VERSION "v1"

NS_ :

BS_:

BU_: ECU0 ECU1 ECU2 ECU3

VAL_TABLE_ TFS 0 "FALSE" 1 "TRUE";
VAL_TABLE_ LRS 0 "LEFT" 1 "RIGHT";
VAL_TABLE_ UDS 0 "UP" 1 "DOWN";
VAL_TABLE_ FooSignalValues ;

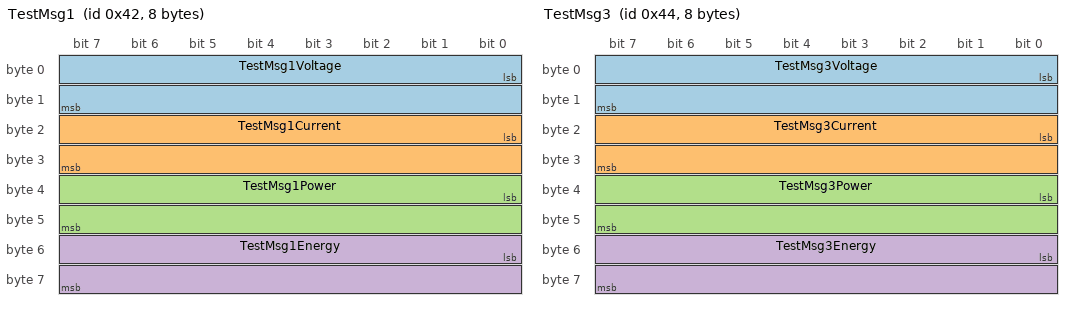
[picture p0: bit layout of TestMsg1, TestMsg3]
BO_ 66 TestMsg1: 8 ECU1
 SG_ TestMsg1Voltage : 0|16@1- (0.001,0) [-32.768|32.767] "V" ECU2,ECU1,ECU0
 SG_ TestMsg1Current : 16|16@1- (0.001,0) [-32.768|32.767] "A" ECU2
 SG_ TestMsg1Power : 32|16@1+ (0.001,0) [0|65.535] "W" ECU2
 SG_ TestMsg1Energy : 48|16@1+ (0.001,100) [100|165.535] "kWh" ECU2

BO_ 67 TestMsg2: 8 ECU1
 SG_ TestMsg2Signal : 0|16@1+ (1,0) [0|10] "Enum" ECU2

BO_ 68 TestMsg3: 8 ECU1
 SG_ TestMsg3Voltage : 0|16@1- (0.001,0) [-32.768|32.767] "V" ECU2
 SG_ TestMsg3Current : 16|16@1- (0.001,1) [-32.768|32.767] "A" ECU2
 SG_ TestMsg3Power : 32|16@1+ (1.0e-3,0) [0|65.535] "W" ECU2
 SG_ TestMsg3Energy : 48|16@1+ (0.001,1e2) [1.e2|165.535] "kWh" ECU2

BO_ 69 TestMsg4: 8 ECU2
 SG_ Muxer M : 0|8@1+ (1,0) [0|3] "" ECU1
 SG_ Muxed0 m0 : 8|8@1+ (1,0) [0|255] "" ECU1
 SG_ Muxed1 m1 : 8|8@1+ (1,0) [0|255] "" ECU1
 SG_ Muxed2 m2 : 8|8@1+ (1,0) [0|255] "" ECU1
 SG_ M : 16|8@1+ (1,0) [0|255] "" ECU1
 SG_ m0 m0 : 24|8@1+ (1,0) [0|255] "" ECU1
 SG_ m1 m1 : 24|8@1+ (1,0) [0|255] "" ECU1
 SG_ m2 m2 : 24|8@1+ (1,0) [0|255] "" ECU1

BO_ 70 TestMsg5: 8 ECU0
 SG_ Foo : 0|8@1+ (1,0) [0|255] "" ECU1

BO_ 71 TestMsg6: 8 ECU0
 SG_ Float1 : 0|32@1+ (1,0) [0|0] "" ECU1
 SG_ Float2 : 32|32@1+ (1,0) [0|0] "" ECU1

BO_TX_BU_ 71 : ECU0, ECU2, ECU3;

EV_ EnvVar1 : 0 [-1|5] "" -1 0 DUMMY_NODE_VECTOR8001 ECU0;
EV_ EnvVar2 : 0 [0|0] "" 0 0 DUMMY_NODE_VECTOR8001 ECU0;
EV_ EnvVar3 : 0 [0|0] "" 0 0 DUMMY_NODE_VECTOR8001 ECU0;

ENVVAR_DATA_ EnvVar2 : 10;
ENVVAR_DATA_ EnvVar3 : 24;

SGTYPE_ FooSignalType : 8@1+ (1,0) [0|255] "" 1 FooSignalValues ;

// Comments go below

CM_ "This is a file
comment
that spans several lines";

CM_ BO_ 66 "This is a \"frame comment\"";
CM_ SG_ 66 TestMsg1Current "This is a signal comment";
CM_ EV_ EnvVar1 "This is a comment for an environment variable #1";
CM_ EV_ EnvVar2 "This is a comment for an environment variable #2";
CM_ EV_ EnvVar3 "This is a comment for an environment variable #3";
CM_ BU_ ECU0 "This is a comment for \"ECU0\"";
CM_ BU_ ECU1 "This is a comment for \"ECU1\"";
CM_ BU_ ECU2 "This is a comment for \"ECU2\"";

// Multiline statements should be ok
     0 "NOP"
     1 "ACT0"
     2 "ACT2"
     -1 "NEG"
     ;

VAL_ 70 Foo 0 "Zero" 1 "One" 2 "Two" 3 "Three";
VAL_ EnvVar1 0 "Zero" 1 "One" 2 "Two" -1 "MinusOne";

SIG_TYPE_REF_ 70 Foo : FooSignalType ;

SIG_GROUP_ 71 FloatValues 1 : Float1 Float2;

SIG_VALTYPE_ 71 Float1 : 1;
SIG_VALTYPE_ 71 Float2 : 1;

SG_MUL_VAL_ 69 m0 M 0-0, 1-1, 2-2;
SG_MUL_VAL_ 69 m1 M 0-0, 1-1, 2-2;
SG_MUL_VAL_ 69 m2 M 0-0, 1-1, 2-2;
